# R7FA4M3AF register map
Vendor: Renesas Electronics Corporation; Series: RA4; File version: 1.40.00
CPU: CM33 r0p4, little endian, MPU, FPU, VTOR, 4 interrupt priority bits, 96 interrupts
Registers are 8-bit, read-write, reset 0x0 unless marked. A register's access mark holds for its fields unless they carry their own. Offsets are from the block's base; [hi:lo] are bit positions; {n}, {i} and the like mark numbered series.

## CACHE
Base 0x40007000
0x00 CCACTL 32-bit — C,Cache Control Register
  [0] ENC — C,Cache Enable
0x04 CCAFCT 32-bit — C,Cache Flush Control Register
  [0] FC — C,Cache Flush
0x08 CCALCF 32-bit reset 0x1 — C,Cache Line Configuration Register
  [1:0] CC — C,Cache Line Size
0x40 SCACTL 32-bit — S,Cache Control Register
  [0] ENS — S,Cache Enable
0x44 SCAFCT 32-bit — S,Cache Flush Control Register
  [0] FS — S,Cache Flush
0x48 SCALCF 32-bit reset 0x1 — S,Cache Line Configuration Register
  [1:0] CS — S,Cache Line Size
0x200 CAPOAD 32-bit — Cache Parity Error Operation After Detection Register
  [0] OAD — Operation after Detection
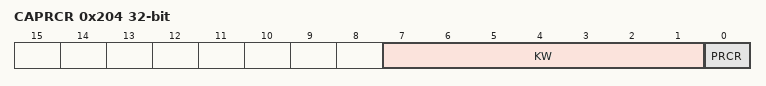
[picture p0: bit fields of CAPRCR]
0x204 CAPRCR 32-bit — Cache Protection Register
  [7:1] KW — Write key code
  [0] PRCR — Register Write Control

## CPSCU — CPU System Security Control Unit
Base 0x40008000
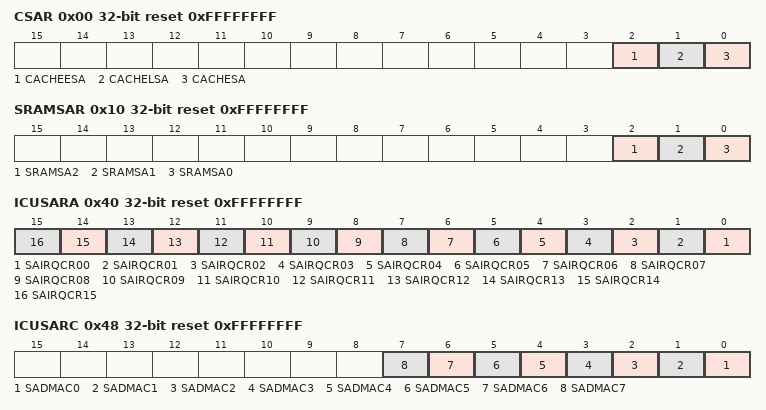
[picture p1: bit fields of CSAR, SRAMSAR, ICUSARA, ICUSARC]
0x00 CSAR 32-bit reset 0xFFFFFFFF — Cache Security Attribution Register
  [2] CACHEESA — Security Attributes of Registers for Cache Error
  [1] CACHELSA — Security Attributes of Registers for Cache Line Configuration
  [0] CACHESA — Security Attributes of Registers for Cache Control
0x10 SRAMSAR 32-bit reset 0xFFFFFFFF — SRAM Security Attribution Register
  [2] SRAMSA2 — Security attributes of registers for ECC Relation
  [1] SRAMSA1 — Security attributes of registers for SRAM Protection 2
  [0] SRAMSA0 — Security attributes of registers for SRAM Protection
0x14 STBRAMSAR 32-bit reset 0xFFFFFFF0 — Standby RAM memory Security Attribution Register
  [3:0] NSBSTBR — Security attributes of each region for Standby RAM
0x30 DTCSAR 32-bit reset 0xFFFFFFFF — DTC Controller Security Attribution Register
  [0] DTCSTSA — DTC Security Attribution
0x34 DMACSAR 32-bit reset 0xFFFFFFFF — DMAC Controller Security Attribution Register
  [0] DMASTSA — DMAST Security Attribution
0x40 ICUSARA 32-bit reset 0xFFFFFFFF — Interrupt Controller Unit Security Attribution Register A
  [n] SAIRQCR{n:02} (n=0..15) — Security attributes of registers for the IRQCRn register
0x44 ICUSARB 32-bit reset 0xFFFFFFFF — Interrupt Controller Unit Security Attribution Register B
  [0] SANMI — Security attributes of registers for nonmaskable interrupt
0x48 ICUSARC 32-bit reset 0xFFFFFFFF — Interrupt Controller Unit Security Attribution Register C
  [n] SADMAC{n} (n=0..7) — Security attributes of registers for DMAC channel
0x4C ICUSARD 32-bit reset 0xFFFFFFFF — Interrupt Controller Unit Security Attribution Register D
  [0] SASELSR0 — Security attributes of registers for SELSR0
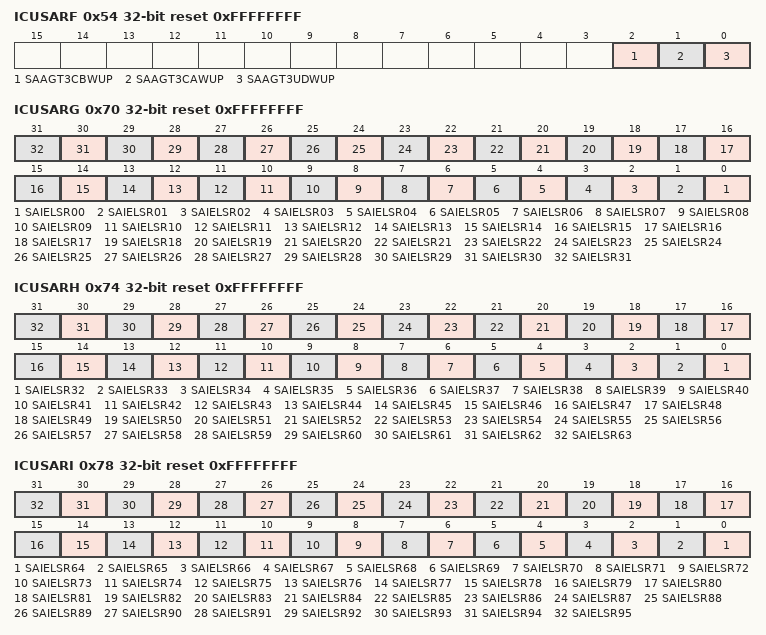
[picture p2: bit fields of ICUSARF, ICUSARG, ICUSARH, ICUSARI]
0x54 ICUSARF 32-bit reset 0xFFFFFFFF — Interrupt Controller Unit Security Attribution Register F
  [2] SAAGT3CBWUP — Security attributes of registers for WUPEN1.b2
  [1] SAAGT3CAWUP — Security attributes of registers for WUPEN1.b1
  [0] SAAGT3UDWUP — Security attributes of registers for WUPEN1.b0
0x70 ICUSARG 32-bit reset 0xFFFFFFFF — Interrupt Controller Unit Security Attribution Register G
  [n] SAIELSR{n:02} (n=0..31) — Security attributes of registers for IELSR31 to IELSR0
0x74 ICUSARH 32-bit reset 0xFFFFFFFF — Interrupt Controller Unit Security Attribution Register H
  [n-32] SAIELSR{n} (n=32..63) — Security attributes of registers for IELSR63 to IELSR32
0x78 ICUSARI 32-bit reset 0xFFFFFFFF — Interrupt Controller Unit Security Attribution Register I
  [n-64] SAIELSR{n} (n=64..95) — Security attributes of registers for IELSR95 to IELSR64
0x100 BUSSARA 32-bit reset 0xFFFFFFFF — BUS Security Attribution Register A
  [0] BUSSA0 — BUS Security Attribution A0
0x104 BUSSARB 32-bit reset 0xFFFFFFFF — BUS Security Attribution Register B
  [0] BUSSB0 — BUS Security Attribution B0
0x130 MMPUSARA 32-bit reset 0xFFFFFFFF — Master Memory Protection Unit Security Attribution Register A
  [7:0] MMPUASAn — MMPUA Security Attribution (n = 0 to 7)
0x134 MMPUSARB 32-bit reset 0xFFFFFFFF — Master Memory Protection Unit Security Attribution Register B
  [0] MMPUBSA0 — MMPUB Security Attribution
0x180 TZFSAR 32-bit reset 0xFFFFFFFE — TrustZone Filter Security Attribution Register
  [0] TZFSA0 — Security attributes of registers for TrustZone Filter
0x1B0 CPUDSAR 32-bit reset 0xFFFFFFFE — CPU Debug Security Attribution Register
  [0] CPUDSA0 — CPU Debug Security Attribution 0

## Notices in the file
This software is supplied by Renesas Electronics Corporation and is only intended for
use with Renesas products. No other uses are authorized. This software is owned by
Renesas Electronics Corporation and is protected under all applicable laws, including
copyright laws.
THIS SOFTWARE IS PROVIDED "AS IS" AND RENESAS MAKES NO WARRANTIES REGARDING
THIS SOFTWARE, WHETHER EXPRESS, IMPLIED OR STATUTORY, INCLUDING BUT NOT LIMITED TO
WARRANTIES OF MERCHANTABILITY, FITNESS FOR A PARTICULAR PURPOSE AND NON-INFRINGEMENT.
ALL SUCH WARRANTIES ARE EXPRESSLY DISCLAIMED. TO THE MAXIMUM EXTENT PERMITTED NOT
PROHIBITED BY LAW, NEITHER RENESAS ELECTRONICS CORPORATION NOR ANY OF ITS AFFILIATED
COMPANIES SHALL BE LIABLE FOR ANY DIRECT, INDIRECT, SPECIAL, INCIDENTAL OR CONSEQUENTIAL
DAMAGES FOR ANY REASON RELATED TO THIS SOFTWARE, EVEN IF RENESAS OR ITS AFFILIATES HAVE
BEEN ADVISED OF THE POSSIBILITY OF SUCH DAMAGES.
Renesas reserves the right, without notice, to make changes to this software and to
discontinue the availability of this software. By using this software, you agree to
the additional terms and conditions found by accessing the following link:
http://www.renesas.com/disclaimer
